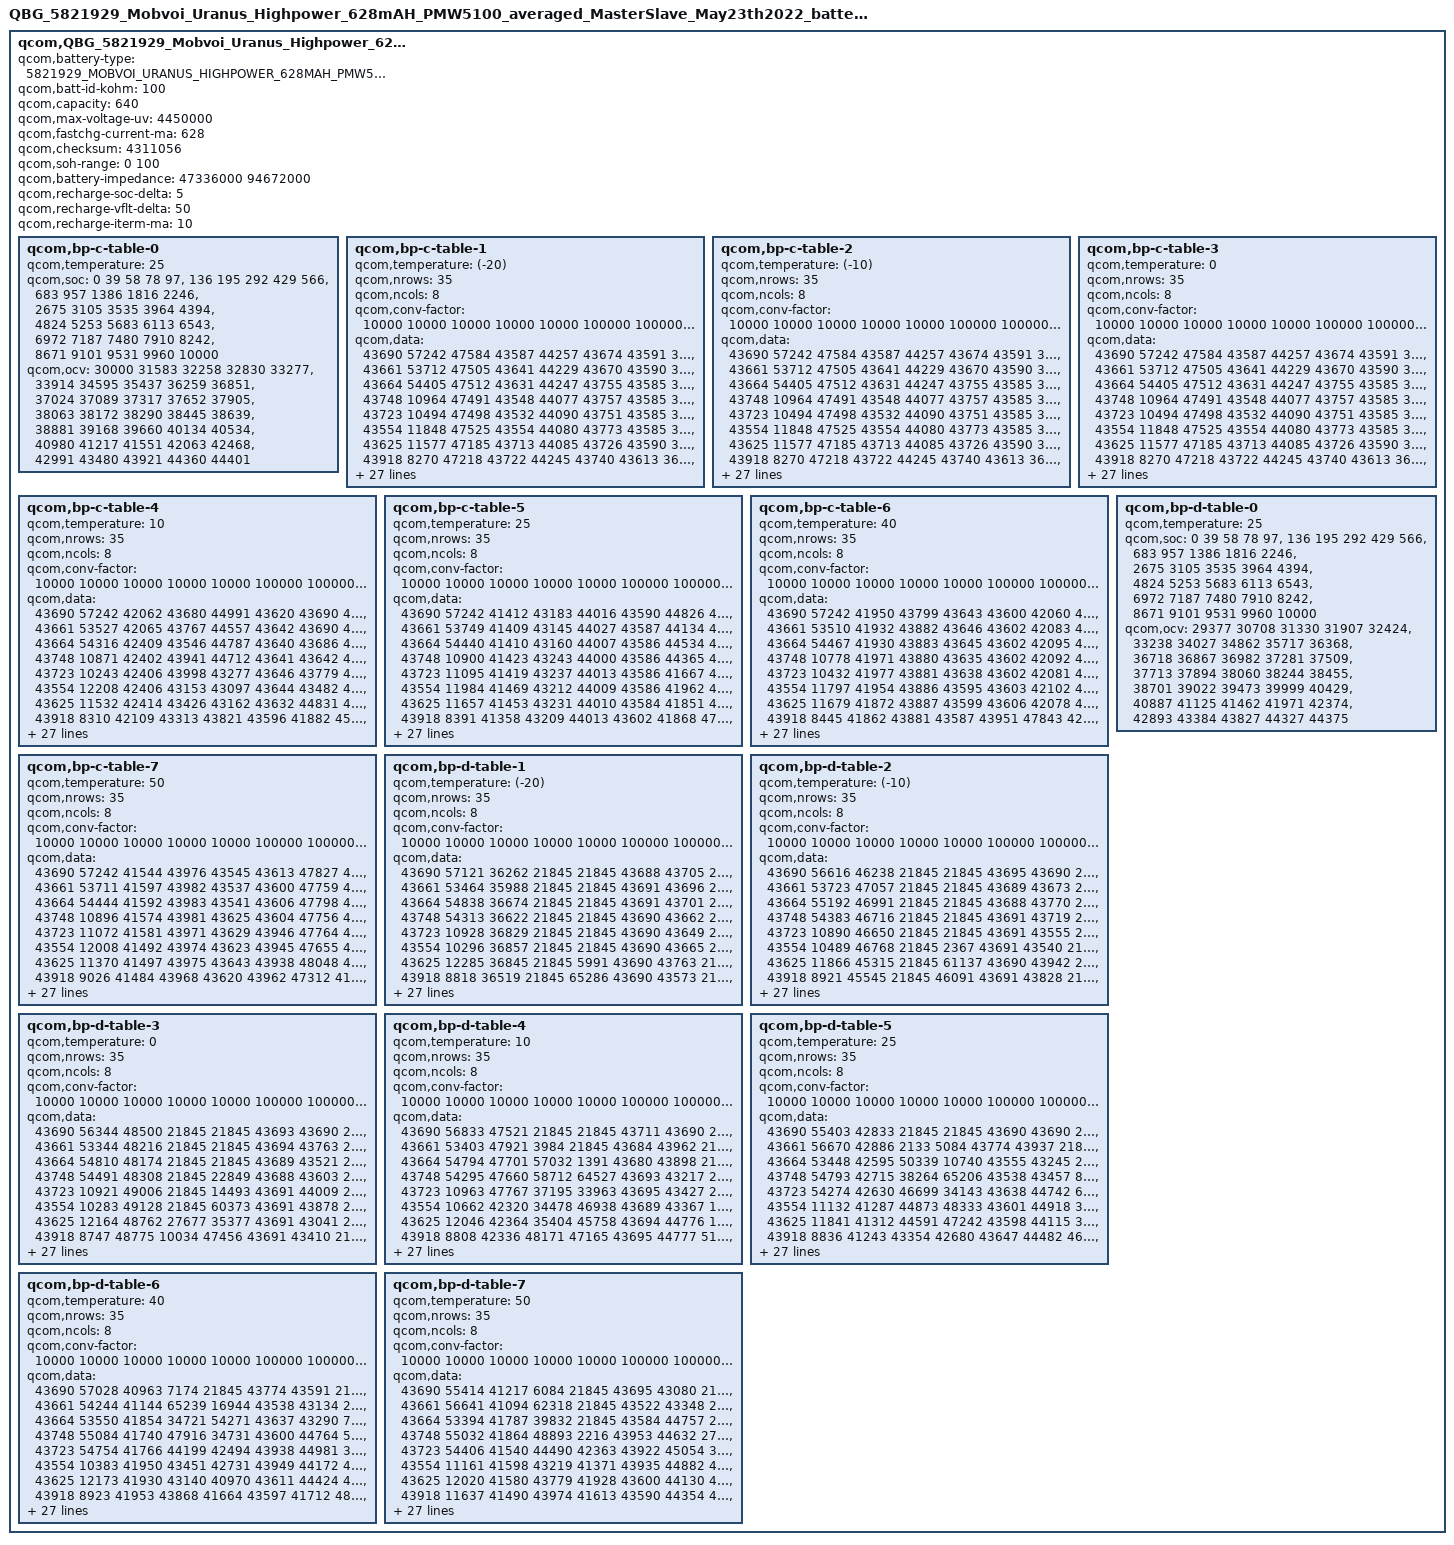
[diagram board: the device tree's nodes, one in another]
/*QBG Profiling Rev. 2.0-Supporting device tree (.dtsi) format*/

qcom,QBG_5821929_Mobvoi_Uranus_Highpower_628mAH_PMW5100_averaged_MasterSlave_May23th2022 {
	qcom,battery-type = "5821929_MOBVOI_URANUS_HIGHPOWER_628MAH_PMW5100_AVERAGED_MASTERSLAVE_MAY23TH2022";
	qcom,batt-id-kohm = <100>;
	qcom,capacity = <640>;
	qcom,max-voltage-uv = <4450000>;
	qcom,fastchg-current-ma = <628>;
	qcom,checksum = <4311056>; /*@5, 0.005V, 4% */
	qcom,soh-range = <0 100>;
	qcom,battery-impedance = <47336000 94672000>; /*Nominal_Impedance in 10nohm @ SOC 50% 25C* 0:fresh cell, 1: aged cell/
	qcom,battery-capacity = <608 480>; /*Nominal_Capacity in mAh. 0: fresh cell, 1:aged cell*/ 
	qcom,recharge-soc-delta =<5>; /*SOC delta (in percent) dropped from EOC SOC to enable recharge*/ 
	qcom,recharge-vflt-delta =<50>; /*vfloat delta (in mV) dropped from regular vfloat in recharge*/ 
	qcom,recharge-iterm-ma = <10>; /*termination current (in mA) in recharge*/ 

	qcom,bp-c-table-0 {
		qcom,temperature = <25>;
		qcom,soc = <    0    39    58    78    97>,
			<  136   195   292   429   566>,
			<  683   957  1386  1816  2246>,
			< 2675  3105  3535  3964  4394>,
			< 4824  5253  5683  6113  6543>,
			< 6972  7187  7480  7910  8242>,
			< 8671  9101  9531  9960 10000>;
		qcom,ocv = <30000 31583 32258 32830 33277>,
			<33914 34595 35437 36259 36851>,
			<37024 37089 37317 37652 37905>,
			<38063 38172 38290 38445 38639>,
			<38881 39168 39660 40134 40534>,
			<40980 41217 41551 42063 42468>,
			<42991 43480 43921 44360 44401>;
	};
	qcom,bp-c-table-1 {
		qcom,temperature = <(-20)>;
		qcom,nrows = <35>;
		qcom,ncols = <8>;
		qcom,conv-factor = <10000 10000 10000 10000 10000 100000 100000 10000>;
		qcom,data = <43690 57242 47584 43587 44257 43674 43591 33749>,
			<43661 53712 47505 43641 44229 43670 43590 33381>,
			<43664 54405 47512 43631 44247 43755 43585 33491>,
			<43748 10964 47491 43548 44077 43757 43585 33420>,
			<43723 10494 47498 43532 44090 43751 43585 36223>,
			<43554 11848 47525 43554 44080 43773 43585 36245>,
			<43625 11577 47185 43713 44085 43726 43590 35880>,
			<43918  8270 47218 43722 44245 43740 43613 36609>,
			<43783  9353 47115 43753 44241 43732 43945 36423>,
			<43164 15041 47117 43653 44259 43534 43951 36542>,
			<43009 15283 47153 43672 44258 43528 43601 35133>,
			<43287 15311 47165 44587 43069 43644 44535 35155>,
			<44992 14563 47140 44105 43121 43631 47979 36612>,
			<44466 14596 47161 44515 43314 43624 47891 36012>,
			<41580 15902 47301 44295 43344 43624 47549 35985>,
			<41177 16368 47354 41656 44681 43541 47527 36088>,
			<42635 16131 47356 41698 44745 43543 47905 35882>,
			<42853 15533 47301 41685 44753 43536 47830 35872>,
			<42454 15405 47329 41507 44563 43549 42808 35865>,
			<48000 15804 47343 41523 45033 43550 42607 36260>,
			<47218 15629 47334 41542 44169 43547 42375 33442>,
			<48687 12814 47261 41863 44890 43525 47285 36182>,
			<48281 12303 47954 41888 43343 43546 47825 36664>,
			<48459 13982 47244 41568 43351 43526 41408 36856>,
			<45861 14198 47940 41888 43320 43520 42730 36747>,
			<45462 13615 47991 41858 43316 43532 41047 36851>,
			<46777  2805 47984 41962 43294 43535 41204 36656>,
			<46994  2866 47949 41775 43379 43528 41851 36026>,
			<46156  2527 47260 41129 44581 43572 41687 36210>,
			<35480  3678 47305 41094 44819 43572 44421 32918>,
			<35701  3161 47349 41145 44309 43535 44872 34656>,
			<35111   604 47161 41924 41396 43546 44555 39339>,
			<36753   126 47168 41660 47666 43547 43457 37359>,
			<35906  1590 47214 44915 42860 43626 43152 37263>,
			<36282  1641 47133 44997 42563 43624 43172 36917>;
	};
	qcom,bp-c-table-2 {
		qcom,temperature = <(-10)>;
		qcom,nrows = <35>;
		qcom,ncols = <8>;
		qcom,conv-factor = <10000 10000 10000 10000 10000 100000 100000 10000>;
		qcom,data = <43690 57242 47584 43587 44257 43674 43591 33749>,
			<43661 53712 47505 43641 44229 43670 43590 33381>,
			<43664 54405 47512 43631 44247 43755 43585 33491>,
			<43748 10964 47491 43548 44077 43757 43585 33420>,
			<43723 10494 47498 43532 44090 43751 43585 36223>,
			<43554 11848 47525 43554 44080 43773 43585 36245>,
			<43625 11577 47185 43713 44085 43726 43590 35880>,
			<43918  8270 47218 43722 44245 43740 43613 36609>,
			<43783  9353 47115 43753 44241 43732 43945 36423>,
			<43164 15041 47117 43653 44259 43534 43951 36542>,
			<43009 15283 47153 43672 44258 43528 43601 35133>,
			<43287 15311 47165 44587 43069 43644 44535 35155>,
			<44992 14563 47140 44105 43121 43631 47979 36612>,
			<44466 14596 47161 44515 43314 43624 47891 36012>,
			<41580 15902 47301 44295 43344 43624 47549 35985>,
			<41177 16368 47354 41656 44681 43541 47527 36088>,
			<42635 16131 47356 41698 44745 43543 47905 35882>,
			<42853 15533 47301 41685 44753 43536 47830 35872>,
			<42454 15405 47329 41507 44563 43549 42808 35865>,
			<48000 15804 47343 41523 45033 43550 42607 36260>,
			<47218 15629 47334 41542 44169 43547 42375 33442>,
			<48687 12814 47261 41863 44890 43525 47285 36182>,
			<48281 12303 47954 41888 43343 43546 47825 36664>,
			<48459 13982 47244 41568 43351 43526 41408 36856>,
			<45861 14198 47940 41888 43320 43520 42730 36747>,
			<45462 13615 47991 41858 43316 43532 41047 36851>,
			<46777  2805 47984 41962 43294 43535 41204 36656>,
			<46994  2866 47949 41775 43379 43528 41851 36026>,
			<46156  2527 47260 41129 44581 43572 41687 36210>,
			<35480  3678 47305 41094 44819 43572 44421 32918>,
			<35701  3161 47349 41145 44309 43535 44872 34656>,
			<35111   604 47161 41924 41396 43546 44555 39339>,
			<36753   126 47168 41660 47666 43547 43457 37359>,
			<35906  1590 47214 44915 42860 43626 43152 37263>,
			<36282  1641 47133 44997 42563 43624 43172 36917>;
	};
	qcom,bp-c-table-3 {
		qcom,temperature = <0>;
		qcom,nrows = <35>;
		qcom,ncols = <8>;
		qcom,conv-factor = <10000 10000 10000 10000 10000 100000 100000 10000>;
		qcom,data = <43690 57242 47584 43587 44257 43674 43591 33749>,
			<43661 53712 47505 43641 44229 43670 43590 33381>,
			<43664 54405 47512 43631 44247 43755 43585 33491>,
			<43748 10964 47491 43548 44077 43757 43585 33420>,
			<43723 10494 47498 43532 44090 43751 43585 36223>,
			<43554 11848 47525 43554 44080 43773 43585 36245>,
			<43625 11577 47185 43713 44085 43726 43590 35880>,
			<43918  8270 47218 43722 44245 43740 43613 36609>,
			<43783  9353 47115 43753 44241 43732 43945 36423>,
			<43164 15041 47117 43653 44259 43534 43951 36542>,
			<43009 15283 47153 43672 44258 43528 43601 35133>,
			<43287 15311 47165 44587 43069 43644 44535 35155>,
			<44992 14563 47140 44105 43121 43631 47979 36612>,
			<44466 14596 47161 44515 43314 43624 47891 36012>,
			<41580 15902 47301 44295 43344 43624 47549 35985>,
			<41177 16368 47354 41656 44681 43541 47527 36088>,
			<42635 16131 47356 41698 44745 43543 47905 35882>,
			<42853 15533 47301 41685 44753 43536 47830 35872>,
			<42454 15405 47329 41507 44563 43549 42808 35865>,
			<48000 15804 47343 41523 45033 43550 42607 36260>,
			<47218 15629 47334 41542 44169 43547 42375 33442>,
			<48687 12814 47261 41863 44890 43525 47285 36182>,
			<48281 12303 47954 41888 43343 43546 47825 36664>,
			<48459 13982 47244 41568 43351 43526 41408 36856>,
			<45861 14198 47940 41888 43320 43520 42730 36747>,
			<45462 13615 47991 41858 43316 43532 41047 36851>,
			<46777  2805 47984 41962 43294 43535 41204 36656>,
			<46994  2866 47949 41775 43379 43528 41851 36026>,
			<46156  2527 47260 41129 44581 43572 41687 36210>,
			<35480  3678 47305 41094 44819 43572 44421 32918>,
			<35701  3161 47349 41145 44309 43535 44872 34656>,
			<35111   604 47161 41924 41396 43546 44555 39339>,
			<36753   126 47168 41660 47666 43547 43457 37359>,
			<35906  1590 47214 44915 42860 43626 43152 37263>,
			<36282  1641 47133 44997 42563 43624 43172 36917>;
	};
	qcom,bp-c-table-4 {
		qcom,temperature = <10>;
		qcom,nrows = <35>;
		qcom,ncols = <8>;
		qcom,conv-factor = <10000 10000 10000 10000 10000 100000 100000 10000>;
		qcom,data = <43690 57242 42062 43680 44991 43620 43690 45514>,
			<43661 53527 42065 43767 44557 43642 43690 45454>,
			<43664 54316 42409 43546 44787 43640 43686 45484>,
			<43748 10871 42402 43941 44712 43641 43642 45133>,
			<43723 10243 42406 43998 43277 43646 43779 45154>,
			<43554 12208 42406 43153 43097 43644 43482 45088>,
			<43625 11532 42414 43426 43162 43632 44831 45190>,
			<43918  8310 42109 43313 43821 43596 41882 45862>,
			<43783  9376 42037 43479 43784 43611 41715 46001>,
			<43164 15083 41997 43477 43814 43610 41803 45678>,
			<43009 14971 42017 43281 44005 43587 42093 45602>,
			<43287 15286 42189 43336 43827 43587 47755 45628>,
			<44992 14522 42189 44598 43115 43639 42007 45947>,
			<44466 14810 42216 44617 43460 43638 42490 45280>,
			<41580 16086 42123 44981 43371 43632 47780 45265>,
			<41177 16316 42171 45045 43341 43644 48047 45105>,
			<42635 16321 42174 44844 43348 43646 48038 45080>,
			<42853 16250 42153 44904 43355 43642 48010 45084>,
			<42454 15562 42845 44888 43340 43617 42007 45073>,
			<48000 15801 42846 44894 44703 43643 41374 45147>,
			<47218 15693 42868 45043 45008 43622 41642 45543>,
			<48687 12869 42855 45010 44861 44015 41233 45374>,
			<48281 12343 42773 44854 44795 43833 42980 45250>,
			<48459 13848 42753 44994 43454 43617 41812 45574>,
			<45861 13465 42807 44816 43445 43618 42721 45649>,
			<45462 13647 42783 44908 43405 43628 41155 46005>,
			<46777  2659 42781 44914 43423 43630 41128 46049>,
			<46994  2215 42771 44887 43516 43624 41783 45837>,
			<46156  2389 42777 44167 43312 43626 41592 45281>,
			<35480  3873 42863 44069 44735 43543 41654 45506>,
			<35701  3390 42144 44136 45010 43543 44143 46914>,
			<35111   806 42228 44239 41629 43619 44937 35646>,
			<36753   511 42190 44818 41331 43642 44731 36007>,
			<35906  1965 42199 43086 42541 43547 43893 36006>,
			<36282  1920 42218 43220 41395 43627 43785 36547>;
	};
	qcom,bp-c-table-5 {
		qcom,temperature = <25>;
		qcom,nrows = <35>;
		qcom,ncols = <8>;
		qcom,conv-factor = <10000 10000 10000 10000 10000 100000 100000 10000>;
		qcom,data = <43690 57242 41412 43183 44016 43590 44826 47664>,
			<43661 53749 41409 43145 44027 43587 44134 47676>,
			<43664 54440 41410 43160 44007 43586 44534 47672>,
			<43748 10900 41423 43243 44000 43586 44365 47655>,
			<43723 11095 41419 43237 44013 43586 41667 47661>,
			<43554 11984 41469 43212 44009 43586 41962 47827>,
			<43625 11657 41453 43231 44010 43584 41851 47861>,
			<43918  8391 41358 43209 44013 43602 41868 47753>,
			<43783  9993 41404 43257 44023 43604 41897 47778>,
			<43164  9561 41046 43863 43820 43937 44518 42264>,
			<43009 14858 41050 43188 43934 43605 42862 42439>,
			<43287 14923 41027 43137 43824 43945 41118 42350>,
			<44992 15215 41059 43058 43048 43943 41930 47706>,
			<44466 14782 40961 43113 43092 43960 40977 48065>,
			<41580 16059 41020 43079 43446 43943 42564 47933>,
			<41177 15877 41006 43435 43437 43950 42009 48083>,
			<42635 16310 41177 43431 43124 43604 42002 48122>,
			<42853 16184 41166 43502 43132 43614 42812 48074>,
			<42454 15495 41212 43299 43124 43610 41446 47872>,
			<48000 15429 41109 43369 43403 43610 41500 47294>,
			<47218 15691 41092 43452 44780 43948 44634 47301>,
			<48687 13226 41136 43110 44658 43588 44250 47136>,
			<48281 12358 41123 43117 43397 43591 41677 47641>,
			<48459 13932 41813 43102 43894 43967 41209 42263>,
			<45861 13564 41811 43517 43806 44009 41330 42366>,
			<45462  2750 41822 43457 43898 43910 41393 47781>,
			<46777  2987 41822 43418 43246 43945 41649 47848>,
			<46994  2277 41822 43452 43033 43591 44170 47674>,
			<46156  3813 41815 43502 43101 43591 44927 48050>,
			<35480  3918 41123 43357 43012 43917 41603 47933>,
			<35701  3397 41099 44729 43471 43607 44055 47164>,
			<35111   882 41193 43341 44630 43611 45036 48786>,
			<36753   315 41153 43313 44348 43606 44743 48128>,
			<35906  2018 41169 43168 44308 43632 43034 48948>,
			<36282  2011 41209 43888 44292 43585 43252 49150>;
	};
	qcom,bp-c-table-6 {
		qcom,temperature = <40>;
		qcom,nrows = <35>;
		qcom,ncols = <8>;
		qcom,conv-factor = <10000 10000 10000 10000 10000 100000 100000 10000>;
		qcom,data = <43690 57242 41950 43799 43643 43600 42060 42496>,
			<43661 53510 41932 43882 43646 43602 42083 42506>,
			<43664 54467 41930 43883 43645 43602 42095 42545>,
			<43748 10778 41971 43880 43635 43602 42092 42556>,
			<43723 10432 41977 43881 43638 43602 42081 42555>,
			<43554 11797 41954 43886 43595 43603 42102 42530>,
			<43625 11679 41872 43887 43599 43606 42078 42710>,
			<43918  8445 41862 43881 43587 43951 47843 42694>,
			<43783 10203 41905 43801 43588 43940 42415 42720>,
			<43164  9484 41915 43839 43614 43904 42167 42635>,
			<43009 15088 41889 43933 43609 43928 42704 41246>,
			<43287 14904 41896 44017 43983 43929 41660 42723>,
			<44992 15309 41554 43780 43848 43930 41521 42937>,
			<44466 14362 41542 43777 43151 43922 41591 42976>,
			<41580 14644 41547 43800 43254 43933 41781 42964>,
			<41177 16122 41596 43781 43138 43904 41469 42899>,
			<42635 15985 41568 43802 43901 43954 41245 42560>,
			<42853 16372 41495 43889 43897 43942 41040 42912>,
			<42454 15524 41477 43865 43863 43604 44319 42988>,
			<48000 15473 41480 43250 43191 43937 44387 42848>,
			<47218 15741 41535 43226 43048 43915 44174 42208>,
			<48687 13195 41504 43819 43323 43912 44684 42132>,
			<48281 12729 41515 43983 43196 43959 44181 42552>,
			<48459 13944 41683 43998 43985 43967 44111 42667>,
			<45861 13504 41689 43817 43834 43961 44188 42634>,
			<45462  2693 41691 43830 43881 43962 44878 42714>,
			<46777  2997 41691 43882 43903 43936 44268 42511>,
			<46994  2266 41688 43890 43863 43949 44189 42566>,
			<46156  3803 41682 43868 43156 43949 44865 42994>,
			<35480  3241 41687 43154 43260 43941 44051 42769>,
			<35701   673 41506 43259 43059 43960 44233 42114>,
			<35111   845 41522 43064 43422 43956 44259 42422>,
			<36753   304 41472 43201 44578 43914 45005 47771>,
			<35906  2036 41524 43994 44560 43967 43488 42449>,
			<36282  1831 41684 44002 44577 43931 43060 42054>;
	};
	qcom,bp-c-table-7 {
		qcom,temperature = <50>;
		qcom,nrows = <35>;
		qcom,ncols = <8>;
		qcom,conv-factor = <10000 10000 10000 10000 10000 100000 100000 10000>;
		qcom,data = <43690 57242 41544 43976 43545 43613 47827 41428>,
			<43661 53711 41597 43982 43537 43600 47759 41262>,
			<43664 54444 41592 43983 43541 43606 47798 41260>,
			<43748 10896 41574 43981 43625 43604 47756 41260>,
			<43723 11072 41581 43971 43629 43946 47764 41260>,
			<43554 12008 41492 43974 43623 43945 47655 41262>,
			<43625 11370 41497 43975 43643 43938 48048 41429>,
			<43918  9026 41484 43968 43620 43962 47312 41411>,
			<43783 10159 41520 43982 43622 43952 47347 41445>,
			<43164  9620 41531 44016 43623 43911 47106 41362>,
			<43009 15025 41511 43594 43644 43978 41166 40991>,
			<43287 15076 41507 43952 43908 43925 41671 41447>,
			<44992 15292 41515 43975 43990 44010 41199 41283>,
			<44466 14539 41683 44019 43800 44001 41965 42671>,
			<41580 14821 41691 44024 43870 44025 41587 42653>,
			<41177 16063 41667 44009 43797 44001 41094 41281>,
			<42635 15901 41674 44011 43974 43928 41466 41268>,
			<42853 16354 41727 43969 43983 43957 40962 41247>,
			<42454 16212 41702 43825 43822 43961 41593 42659>,
			<48000 15475 41704 43793 43873 43960 44101 42693>,
			<47218 15735 41619 43884 43143 43961 45002 42614>,
			<48687 13210 41605 44005 43107 44009 44716 42613>,
			<48281 12725 41602 43918 43810 43922 44501 41422>,
			<48459 13951 41608 43908 43918 43908 41513 41387>,
			<45861 13529 41655 43926 43933 43910 44305 41358>,
			<45462  2708 41648 44015 43986 43917 44073 41415>,
			<46777  2970 41651 44005 43838 43912 44182 41279>,
			<46994  2088 41651 43981 43806 43956 44232 41339>,
			<46156  3624 41649 43812 43848 43952 44058 42630>,
			<35480  3262 41655 43829 43173 43967 44253 42693>,
			<35701   703 41609 43897 43166 43962 44436 42597>,
			<35111   836 41606 43864 43019 43952 44037 42970>,
			<36753   311 41631 43851 43484 43928 44201 42120>,
			<35906  1996 41650 43949 43274 43907 43512 42995>,
			<36282  1852 44379 43539 44715 43956 43250 42979>;
	};
	qcom,bp-d-table-0 {
		qcom,temperature = <25>;
		qcom,soc = <    0    39    58    78    97>,
			<  136   195   292   429   566>,
			<  683   957  1386  1816  2246>,
			< 2675  3105  3535  3964  4394>,
			< 4824  5253  5683  6113  6543>,
			< 6972  7187  7480  7910  8242>,
			< 8671  9101  9531  9960 10000>;
		qcom,ocv = <29377 30708 31330 31907 32424>,
			<33238 34027 34862 35717 36368>,
			<36718 36867 36982 37281 37509>,
			<37713 37894 38060 38244 38455>,
			<38701 39022 39473 39999 40429>,
			<40887 41125 41462 41971 42374>,
			<42893 43384 43827 44327 44375>;
	};
	qcom,bp-d-table-1 {
		qcom,temperature = <(-20)>;
		qcom,nrows = <35>;
		qcom,ncols = <8>;
		qcom,conv-factor = <10000 10000 10000 10000 10000 100000 100000 10000>;
		qcom,data = <43690 57121 36262 21845 21845 43688 43705 21845>,
			<43661 53464 35988 21845 21845 43691 43696 21845>,
			<43664 54838 36674 21845 21845 43691 43701 21845>,
			<43748 54313 36622 21845 21845 43690 43662 21845>,
			<43723 10928 36829 21845 21845 43690 43649 21845>,
			<43554 10296 36857 21845 21845 43690 43665 21845>,
			<43625 12285 36845 21845  5991 43690 43763 21845>,
			<43918  8818 36519 21845 65286 43690 43573 21845>,
			<43783  9916 35319 21845 32794 43690 43955 21845>,
			<43164  9376 35608 21845 46611 43691 43878 21845>,
			<43009  9286 35737 24666 49101 43691 43158 21845>,
			<43287  9596 35781 13034 47130 43691 43175 21845>,
			<44992 14861 35622 10461 47509 43688 43853 21845>,
			<44466 15348 35612 55612 47266 43688 43866 21845>,
			<41580 14527 35408 50037 47877 43688 43856 21845>,
			<41177 14445 35715 62944 47928 43688 43863 21927>,
			<42635 14790 35756 65518 48123 43688 43183 22953>,
			<42853 16043 35398 57670 48062 43688 43871 19955>,
			<42454 15905 35761 59642 47623 43688 43866 30349>,
			<48000 16288 35782 37671 47647 43688 43880 31580>,
			<47218 16164 35835 39055 47623 43688 43805 25575>,
			<48687 15491 35810 34449 47658 43688 43887 27480>,
			<48281 15784 35631 33474 47670 43688 43197  5890>,
			<48459 13005 35632 36280 47501 43688 43450  5742>,
			<45861 12510 35404 33397 45925 43689 44583 28356>,
			<45462 14063 35821 32893 46268 43688 44576 24810>,
			<46777 14196 35725 33274 35866 43689 44651 31013>,
			<46994  2611 35432 34393 37300 43689 44807 16953>,
			<46156  3058 35411 34433 40694 43689 43430 19413>,
			<35480  2252 35759 34131 39663 43689 43087 18748>,
			<35701  3590 35768 37222 34068 43689 43498 23149>,
			<35111  3500 35715 61437 38924 43688 43439 21873>,
			<36753   780 35718 63924 34274 43688 43845 21845>,
			<35906  1943 35412 51482 36676 43688 43618 21845>,
			<36282  1847 35423 53230 36369 43688 43539 21845>;
	};
	qcom,bp-d-table-2 {
		qcom,temperature = <(-10)>;
		qcom,nrows = <35>;
		qcom,ncols = <8>;
		qcom,conv-factor = <10000 10000 10000 10000 10000 100000 100000 10000>;
		qcom,data = <43690 56616 46238 21845 21845 43695 43690 21845>,
			<43661 53723 47057 21845 21845 43689 43673 21845>,
			<43664 55192 46991 21845 21845 43688 43770 21845>,
			<43748 54383 46716 21845 21845 43691 43719 21845>,
			<43723 10890 46650 21845 21845 43691 43555 21845>,
			<43554 10489 46768 21845  2367 43691 43540 21845>,
			<43625 11866 45315 21845 61137 43690 43942 21845>,
			<43918  8921 45545 21845 46091 43691 43828 21845>,
			<43783  8542 45907  1927 47834 43691 43238 21845>,
			<43164  9445 45206 14900 48045 43691 43020 21845>,
			<43009  9609 45853 10369 47823 43691 43214 21845>,
			<43287  9488 45239 51105 42543 43691 43140 22991>,
			<44992 15071 45856 51354 42717 43688 43189 20443>,
			<44466 15147 45235 62395 42887 43688 43216 28789>,
			<41580 14534 45234 64203 42788 43688 43015 31296>,
			<41177 14775 45842 60658 42978 43688 43058 28407>,
			<42635 14598 45859 36896 42524 43688 43216  7370>,
			<42853 16011 45828 33984 42678 43688 43157  3525>,
			<42454 15906 46016 35302 41284 43688 43840 13156>,
			<48000 15963 45948 45087 41230 43689 43853 10034>,
			<47218 16322 45894 47433 41254 43689 43840 10263>,
			<48687 15584 45932 47502 42710 43689 43304 54637>,
			<48281 12961 45836 48982 47269 43695 44159 10329>,
			<48459 12457 45942 48943 45556 43693 44869  9010>,
			<45861 12642 45834 49054 46388 43680 44750  8689>,
			<45462 13399 45835 48844 39011 43733 44874  2986>,
			<46777 13677 45839 47576 39368 43560 45031  2666>,
			<46994  2769 45873 47887 39702 43737 43094 14004>,
			<46156  2108 45838 46291 33637 43554 45049  2920>,
			<35480  3715 45831 35575 33537 43732 45041  3995>,
			<35701  3200 45824 35482 34806 43725 44738   802>,
			<35111   715 46038 35696 34234 43727 43383  1247>,
			<36753   216 45967 36516 36492 43757 43118  1591>,
			<35906  2030 45679 35897 48718 43651 43992  2447>,
			<36282  1831 45588 35942 47468 43650 44031  2842>;
	};
	qcom,bp-d-table-3 {
		qcom,temperature = <0>;
		qcom,nrows = <35>;
		qcom,ncols = <8>;
		qcom,conv-factor = <10000 10000 10000 10000 10000 100000 100000 10000>;
		qcom,data = <43690 56344 48500 21845 21845 43693 43690 21845>,
			<43661 53344 48216 21845 21845 43694 43763 21845>,
			<43664 54810 48174 21845 21845 43689 43521 21845>,
			<43748 54491 48308 21845 22849 43688 43603 21845>,
			<43723 10921 49006 21845 14493 43691 44009 21845>,
			<43554 10283 49128 21845 60373 43691 43878 21845>,
			<43625 12164 48762 27677 35377 43691 43041 21845>,
			<43918  8747 48775 10034 47456 43691 43410 21845>,
			<43783  8513 47446 57016 47201 43691 43312 21035>,
			<43164  9398 48802 52939 47494 43691 43298 20374>,
			<43009  9299 47482 61921 48119 43691 43463 32125>,
			<43287  9518 47422 60571 42667 43688 43010  4759>,
			<44992 15092 47414 37529 41013 43688 43134  4060>,
			<44466 15160 47572 36380 41382 43688 43451  9899>,
			<41580 14391 47406 48634 41428 43689 43343 56626>,
			<41177 14826 47560 42952 41463 43694 43426 52882>,
			<42635 14616 47557 41545 41826 43682 43059 65177>,
			<42853 16059 47605 44053 44393 43702 43050 58043>,
			<42454 16093 47574 43784 41942 43700 43883 38214>,
			<48000 16317 47597 44562 44343 43743 44905 38641>,
			<47218 15497 47602 44419 41718 43527 44322 38460>,
			<48687 15678 47579 44314 42999 43548 44154 38395>,
			<48281 13286 47587 41495 47294 43541 44275 59888>,
			<48459 12767 47569 41002 45991 43623 44878 57834>,
			<45861 14081 47501 42750 46412 43628 44835 63982>,
			<45462 13703 47519 41358 46180 43624 43427 64134>,
			<46777  2725 47592 42685 47007 43536 43511 64181>,
			<46994  3035 47614 42327 46060 43529 44931 64013>,
			<46156  2556 47608 42097 45831 43529 44571 64059>,
			<35480  3648 47495 42184 45500 43535 44579 64324>,
			<35701  3488 47525 42237 47007 43520 44740 64693>,
			<35111   928 47492 42027 46896 43526 44733 62133>,
			<36753   117 47495 42869 48904 43580 43279 63949>,
			<35906  2027 47544 42562 42537 43728 43441 58152>,
			<36282  2004 47527 42622 42680 43731 43428 58054>;
	};
	qcom,bp-d-table-4 {
		qcom,temperature = <10>;
		qcom,nrows = <35>;
		qcom,ncols = <8>;
		qcom,conv-factor = <10000 10000 10000 10000 10000 100000 100000 10000>;
		qcom,data = <43690 56833 47521 21845 21845 43711 43690 21845>,
			<43661 53403 47921  3984 21845 43684 43962 21845>,
			<43664 54794 47701 57032  1391 43680 43898 21845>,
			<43748 54295 47660 58712 64527 43693 43217 21845>,
			<43723 10963 47767 37195 33963 43695 43427 27235>,
			<43554 10662 42320 34478 46938 43689 43367 13280>,
			<43625 12046 42364 35404 45758 43694 44776 10523>,
			<43918  8808 42336 48171 47165 43695 44777 51070>,
			<43783  9899 42276 42066 42108 43680 43330 62214>,
			<43164  9420 42300 41365 42040 43698 44731 58719>,
			<43009  9725 42296 41737 42974 43663 44713 57741>,
			<43287  9587 42292 44111 41592 43668 44698 38499>,
			<44992 14885 42301 44192 41657 43741 44630 40012>,
			<44466 15205 42482 45014 44489 43530 44910 34047>,
			<41580 14440 42442 44608 44252 43538 44200 36157>,
			<41177 14793 42399 44600 44850 43616 44134 35272>,
			<42635 14699 42406 44693 44710 43642 44526 46405>,
			<42853 16102 42079 44699 44562 43620 44396 46584>,
			<42454 16295 42050 44797 44916 43620 44486 46339>,
			<48000 16198 42080 44590 44268 43643 44457 46546>,
			<47218 15448 41989 44573 44037 43641 44121 46544>,
			<48687 12951 42034 44962 44356 43646 44111 35384>,
			<48281 13138 42017 44809 41251 43638 44287 36404>,
			<48459 13965 41999 44065 47706 43587 44628 32832>,
			<45861 14197 42028 44085 47869 43645 43438 32964>,
			<45462 13577 42023 44385 42699 43626 43345 36213>,
			<46777  2596 42040 44401 41316 43542 44689 36133>,
			<46994  2929 42037 44301 41255 43539 44762 36315>,
			<46156  2428 42015 44483 41341 43537 44571 33450>,
			<35480  4032 42105 44531 42694 43540 44665 33701>,
			<35701  3551 42054 44524 42790 43625 44665 33214>,
			<35111   971 42049 44115 42113 43618 44598 34545>,
			<36753   394 42426 44076 41409 43628 44569 32876>,
			<35906  1941 42478 44881 44465 43542 44988 36695>,
			<36282  2015 42467 44868 44055 43536 44942 36848>;
	};
	qcom,bp-d-table-5 {
		qcom,temperature = <25>;
		qcom,nrows = <35>;
		qcom,ncols = <8>;
		qcom,conv-factor = <10000 10000 10000 10000 10000 100000 100000 10000>;
		qcom,data = <43690 55403 42833 21845 21845 43690 43690 21845>,
			<43661 56670 42886  2133  5084 43774 43937 21845>,
			<43664 53448 42595 50339 10740 43555 43245 21845>,
			<43748 54793 42715 38264 65206 43538 43457   802>,
			<43723 54274 42630 46699 34143 43638 44742 62505>,
			<43554 11132 41287 44873 48333 43601 44918 33182>,
			<43625 11841 41312 44591 47242 43598 44115 36797>,
			<43918  8836 41243 43354 42680 43647 44482 46215>,
			<43783  8495 41264 43481 44057 43646 44433 45731>,
			<43164  9402 41426 43440 44551 43592 44225 49126>,
			<43009  9668 41419 43426 44618 43588 44937 49132>,
			<43287 15017 41458 43051 43487 43590 44847 47531>,
			<44992 15068 41363 43243 43086 43603 44168 47991>,
			<44466 15115 41396 43170 43017 43603 44897 48052>,
			<41580 14383 41046 43179 43225 43605 44109 47622>,
			<41177 14843 41031 43139 43287 43604 44306 47948>,
			<42635 16044 41085 43243 44650 43939 44110 47231>,
			<42853 15878 40990 43263 44736 43943 44042 47306>,
			<42454 16334 40997 43255 43381 43940 44065 47898>,
			<48000 15517 41183 43236 43507 43939 44191 47710>,
			<47218 15751 41205 43157 43422 43605 44916 47625>,
			<48687 12996 41210 43255 43279 43607 44912 48014>,
			<48281 12443 41187 43437 44261 43948 44223 48849>,
			<48459 13973 41111 43468 41602 43938 43483 48150>,
			<45861 14151 41112 43491 44889 43588 43429 48839>,
			<45462 13597 41104 43410 44669 43592 43467 47586>,
			<46777  2575 41109 43404 44756 43637 43461 47217>,
			<46994  2908 41197 43091 44684 43636 43480 47349>,
			<46156  2393 41214 43111 43364 43632 43317 47940>,
			<35480  3884 41167 43028 43316 43632 43343 47974>,
			<35701  3367 41006 43035 43298 43639 44785 47980>,
			<35111   978 40970 43060 43325 43598 44646 47937>,
			<36753   409 40983 43221 43288 43615 45019 47288>,
			<35906  1933 41073 43210 43387 43936 44195 47254>,
			<36282  2045 41076 43253 43385 43942 44219 47253>;
	};
	qcom,bp-d-table-6 {
		qcom,temperature = <40>;
		qcom,nrows = <35>;
		qcom,ncols = <8>;
		qcom,conv-factor = <10000 10000 10000 10000 10000 100000 100000 10000>;
		qcom,data = <43690 57028 40963  7174 21845 43774 43591 21845>,
			<43661 54244 41144 65239 16944 43538 43134 21845>,
			<43664 53550 41854 34721 54271 43637 43290  7866>,
			<43748 55084 41740 47916 34731 43600 44764 57484>,
			<43723 54754 41766 44199 42494 43938 44981 35512>,
			<43554 10383 41950 43451 42731 43949 44172 45835>,
			<43625 12173 41930 43140 40970 43611 44424 48198>,
			<43918  8923 41953 43868 41664 43597 41712 48895>,
			<43783  8497 41876 43898 43516 43600 41494 42402>,
			<43164  9398 41882 43800 43185 43945 41699 42802>,
			<43009  9676 41860 43873 43207 43943 44081 42159>,
			<43287  9545 41864 44017 43193 43953 44942 42882>,
			<44992 15077 41904 43935 43795 43909 44264 42553>,
			<44466 15323 41894 43915 43887 44013 44916 42709>,
			<41580 14585 41557 43965 43867 43933 44160 42530>,
			<41177 14724 41543 43912 43213 43920 44906 42576>,
			<42635 16008 41588 44019 43328 44024 44910 41985>,
			<42853 15981 41573 44014 43511 44012 44972 42845>,
			<42454 16336 41578 43926 43024 43932 44971 42990>,
			<48000 15590 41497 43929 43232 43931 44983 42518>,
			<47218 15851 41484 43911 43150 43910 44985 42541>,
			<48687 12847 41483 44027 43067 43919 44959 42931>,
			<48281 12518 41482 43863 44698 43906 44829 42459>,
			<48459 14063 41523 43237 44756 43965 43351 47758>,
			<45861 14158 41522 43173 43467 43613 43361 42095>,
			<45462 13581 41520 43794 43073 43606 43471 42832>,
			<46777  2622 41526 43806 43032 43600 43485 42771>,
			<46994  2894 41483 43795 43214 43615 43348 42973>,
			<46156  2378 41475 43803 43195 43606 44554 42933>,
			<35480  4058 41496 43791 43847 43605 44626 42590>,
			<35701  3550 41576 43811 43893 43947 44981 42616>,
			<35111  1015 41594 43976 43866 43938 44990 42606>,
			<36753   438 41589 44007 43172 43953 45003 42623>,
			<35906  1977 41543 44005 43161 43930 44905 42918>,
			<36282  2025 41540 44027 43164 43928 44899 42937>;
	};
	qcom,bp-d-table-7 {
		qcom,temperature = <50>;
		qcom,nrows = <35>;
		qcom,ncols = <8>;
		qcom,conv-factor = <10000 10000 10000 10000 10000 100000 100000 10000>;
		qcom,data = <43690 55414 41217  6084 21845 43695 43080 21845>,
			<43661 56641 41094 62318 21845 43522 43348 21845>,
			<43664 53394 41787 39832 21845 43584 44757 21845>,
			<43748 55032 41864 48893  2216 43953 44632 27612>,
			<43723 54406 41540 44490 42363 43922 45054 35788>,
			<43554 11161 41598 43219 41371 43935 44882 48620>,
			<43625 12020 41580 43779 41928 43600 44130 48852>,
			<43918 11637 41490 43974 41613 43590 44354 47182>,
			<43783  8637 41484 44031 43441 43946 41529 42758>,
			<43164  9987 41521 44006 43903 43962 41924 42727>,
			<43009  9649 41523 44020 43177 43960 44525 42528>,
			<43287  9498 41529 43919 43778 43930 44890 41283>,
			<44992 15038 41510 43945 44024 44011 44368 41417>,
			<44466 15261 41512 43597 43991 44024 44094 41417>,
			<41580 14517 41693 43632 43881 43983 44263 41279>,
			<41177 14421 41668 43636 43869 43977 44802 41239>,
			<42635 16050 41673 43605 43396 43994 45038 42917>,
			<42853 15981 41712 43940 43024 43994 44934 42511>,
			<42454 16343 41701 43603 43165 43982 44626 42664>,
			<48000 15608 41711 43614 43889 44026 45000 41266>,
			<47218 15840 41620 43614 43805 44002 44830 41438>,
			<48687 12838 41619 43955 43178 43926 44894 41288>,
			<48281 12519 41630 43835 43404 43919 44193 42810>,
			<48459 13973 41624 43779 43483 43964 43358 42837>,
			<45861 14199 41624 43981 43014 43967 43316 42577>,
			<45462 13576 41627 43819 43185 43936 44591 42711>,
			<46777  2596 41624 43817 43855 43949 44967 42726>,
			<46994  2935 41630 43816 43776 43950 44823 42680>,
			<46156  2429 41617 43972 43990 43945 44228 41316>,
			<35480  4044 41706 44019 43968 43951 44142 41228>,
			<35701  3533 41709 43924 43976 43943 44108 41257>,
			<35111   997 41701 43912 43968 43907 44131 41439>,
			<36753   442 41721 43942 43812 44014 44141 41424>,
			<35906  1962 41726 43605 43807 44022 44149 41272>,
			<36282  1925 41726 43604 43805 44023 44105 41276>;
	};
};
